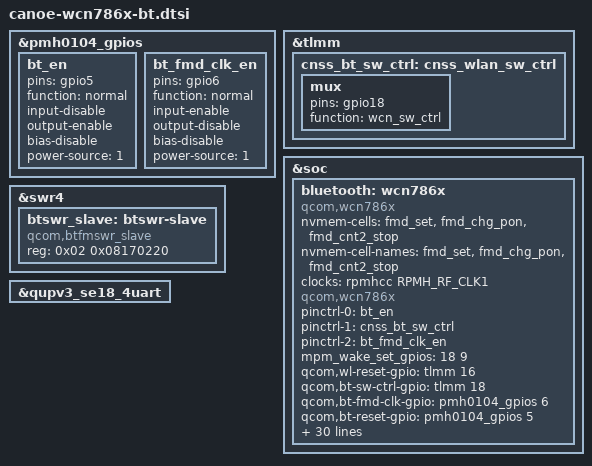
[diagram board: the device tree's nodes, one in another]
// SPDX-License-Identifier: BSD-3-Clause

/*
 * Copyright (c) 2024 Qualcomm Innovation Center, Inc. All rights reserved.
 */

#include <dt-bindings/interconnect/qcom,canoe.h>
#include <dt-bindings/clock/qcom,rpmh.h>

&pmh0104_gpios {
	bt_en: bt_en {
		pins = "gpio5";
		function = "normal";
		input-disable;
		output-enable;
		bias-disable;
		power-source = <1>;
	};
	bt_fmd_clk_en: bt_fmd_clk_en {
		pins = "gpio6";
		function = "normal";
		input-enable;
		output-disable;
		bias-disable;
		power-source = <1>;
	};
};

&tlmm {
	cnss_bt_sw_ctrl: cnss_wlan_sw_ctrl {
		mux {
			pins = "gpio18";
			function = "wcn_sw_ctrl";
		};
	};
};

&soc {
	bluetooth: wcn786x {
			compatible = "qcom,wcn786x";
			nvmem-cells = <&fmd_set>, <&fmd_chg_pon>, <&fmd_cnt2_stop>;
			nvmem-cell-names = "fmd_set", "fmd_chg_pon", "fmd_cnt2_stop";
			clocks = <&rpmhcc RPMH_RF_CLK1>;
			clock-names = "bt_rf_clk1";
			qcom,wcn786x;
			pinctrl-names = "bt_en", "sw_ctrl", "bt_fmd_clk_en";
			pinctrl-0 = <&bt_en>;
			pinctrl-1 = <&cnss_bt_sw_ctrl>;
			pinctrl-2 = <&bt_fmd_clk_en>;
			/* List of GPIOs to be setup for interrupt wakeup capable*/
			mpm_wake_set_gpios = <18 9>;
			qcom,wl-reset-gpio = <&tlmm 16 0>; /* WL_EN */
			qcom,bt-sw-ctrl-gpio = <&tlmm 18 0>; /* SW_CTRL */
			qcom,bt-fmd-clk-gpio = <&pmh0104_gpios 6 0>; /* FMD_CLK_CTRL */
			qcom,bt-reset-gpio = <&pmh0104_gpios 5 0>; /* BT_EN */
			qcom,qmp = <&aoss_qmp>;

			qcom,bt-vdd18-aon-supply  = <&L2G>;   /* VDD1P8_AON */
			qcom,bt-vdd12-io-supply   = <&L3G>;   /* VDD1P2_IO */
			qcom,bt-ant-ldo-supply    = <&L6K>;   /* AV91C_VDD Extractor */
			qcom,bt-vdd-dig-supply    = <&S2J>;   /* BT CX_MX LDO */
			qcom,bt-vdd-aon-supply    = <&S2J>;   /* RFA_CMN/AON */
			qcom,bt-vdd-rfa0p75-supply = <&S2J>;  /* RFA_OP75 */
			qcom,bt-vdd-rfa1p8-supply  = <&S8F>;  /* RFA_1P8 */
			qcom,bt-vdd-rfa1p25-supply = <&S7F>; /* RFA_1P2 */

			qcom,bt-vdd18-aon-config  = <1800000 1800000 30000 1 1>;
			qcom,bt-vdd12-io-config   = <1200000 1200000 30000 1 1>;
			qcom,bt-ant-ldo-config    = <1800000 1860000 0 1 0>;
			qcom,bt-vdd-aon-config    = <892000 1036000 0 1 0>;
			qcom,bt-vdd-dig-config    = <892000 1036000 0 1 1>;
			qcom,bt-vdd-rfa0p75-config = <892000 1036000 0 1 0>;
			qcom,bt-vdd-rfa1p8-config = <1876000 2000000 0 1 0>;
			qcom,bt-vdd-rfa1p25-config  = <1328000 1340000 0 1 0>;

			/* WLAN CX regulator for FMD feature */
			qcom,bt-vdd-wlan-aon-supply = <&S1J>;
			qcom,bt-vdd-wlan-aon-config = <892000 1000000 0 0 1>;

			qcom,pdc_init_table =
				"{class: wlan_pdc, ss: rf, res: S2J1.m, enable: 1}", // to be checked
				"{class: wlan_pdc, ss: rf, res: S2J1.v, enable: 1}", // to be checked
				"{class: wlan_pdc, ss: rf, res: S2J1.v, upval: 876}", // to be checked
				"{class: wlan_pdc, ss: rf, res: S2J1.v, dwnval: 876}"; // to be checked
	};
};

&swr4 {
	btswr_slave: btswr-slave {
		compatible = "qcom,btfmswr_slave";
		reg = <0x02 0x08170220>;
	};
};

//uart instance
&qupv3_se18_4uart {
	status = "ok";
};
